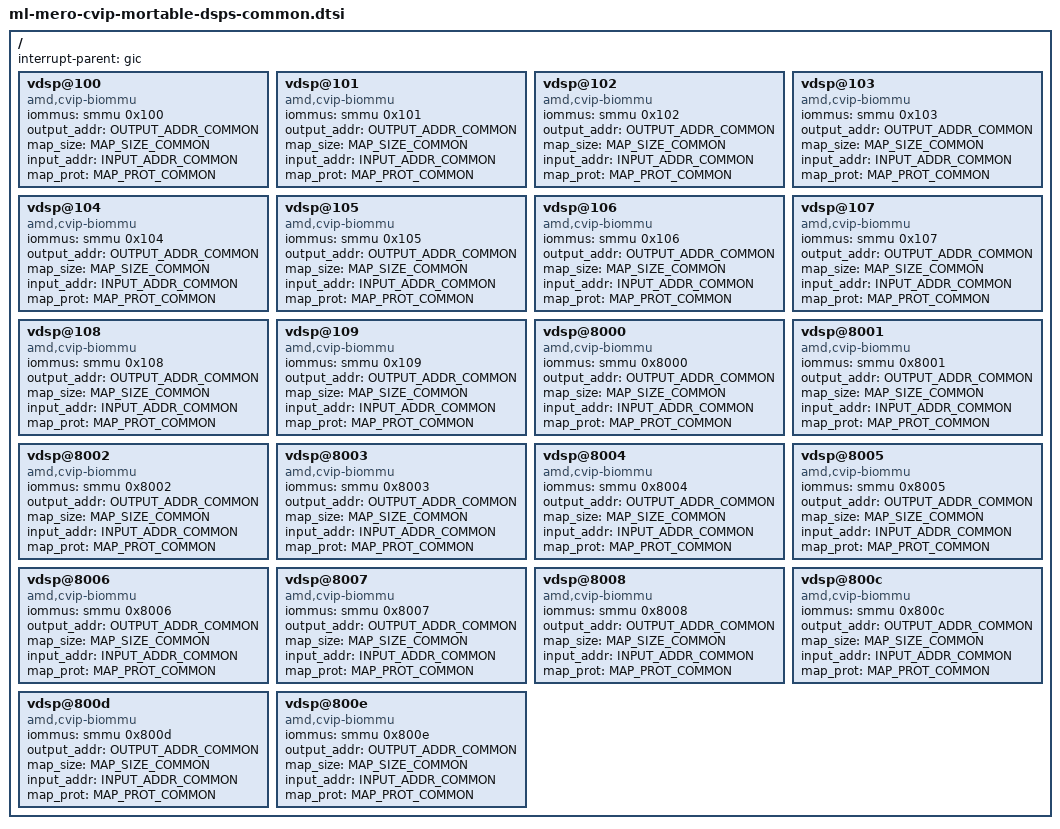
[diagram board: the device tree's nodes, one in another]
/*
 * DTS file for DSP Stream IDs
 *
 * Copyright (C) 2018-2020 Advanced Micro Devices, Inc. All rights reserved.
 */

#include <dt-bindings/interrupt-controller/irq.h>
#include <dt-bindings/interrupt-controller/arm-gic.h>
#include <dt-bindings/cvcore/cvcore_common.h>

/dts-v1/;

/ {
	interrupt-parent = <&gic>;
	#size-cells = <0x2>;
	#address-cells = <0x2>;

	vdsp@100 {
		status = "ok";
		compatible = "amd,cvip-biommu";
		iommus = <&smmu 0x100>;
		output_addr = OUTPUT_ADDR_COMMON;
		map_size = MAP_SIZE_COMMON;
		input_addr = INPUT_ADDR_COMMON;
		map_prot = MAP_PROT_COMMON;
	};

	vdsp@101 {
		status = "ok";
		compatible = "amd,cvip-biommu";
		iommus = <&smmu 0x101>;
		output_addr = OUTPUT_ADDR_COMMON;
		map_size = MAP_SIZE_COMMON;
		input_addr = INPUT_ADDR_COMMON;
		map_prot = MAP_PROT_COMMON;
	};

    // Stream ID for cvcore_component validation
	vdsp@102 {
		status = "ok";
		compatible = "amd,cvip-biommu";
		iommus = <&smmu 0x102>;
		output_addr = OUTPUT_ADDR_COMMON;
		map_size = MAP_SIZE_COMMON;
		input_addr = INPUT_ADDR_COMMON;
		map_prot = MAP_PROT_COMMON;
	};

	vdsp@103 {
		status = "ok";
		compatible = "amd,cvip-biommu";
		iommus = <&smmu 0x103>;
		output_addr = OUTPUT_ADDR_COMMON;
		map_size = MAP_SIZE_COMMON;
		input_addr = INPUT_ADDR_COMMON;
		map_prot = MAP_PROT_COMMON;
	};

	vdsp@104 {
		status = "ok";
		compatible = "amd,cvip-biommu";
		iommus = <&smmu 0x104>;
		output_addr = OUTPUT_ADDR_COMMON;
		map_size = MAP_SIZE_COMMON;
		input_addr = INPUT_ADDR_COMMON;
		map_prot = MAP_PROT_COMMON;
	};

	vdsp@105 {
		status = "ok";
		compatible = "amd,cvip-biommu";
		iommus = <&smmu 0x105>;
		output_addr = OUTPUT_ADDR_COMMON;
		map_size = MAP_SIZE_COMMON;
		input_addr = INPUT_ADDR_COMMON;
		map_prot = MAP_PROT_COMMON;
	};

	vdsp@106 {
		status = "ok";
		compatible = "amd,cvip-biommu";
		iommus = <&smmu 0x106>;
		output_addr = OUTPUT_ADDR_COMMON;
		map_size = MAP_SIZE_COMMON;
		input_addr = INPUT_ADDR_COMMON;
		map_prot = MAP_PROT_COMMON;
	};

	vdsp@107 {
		status = "ok";
		compatible = "amd,cvip-biommu";
		iommus = <&smmu 0x107>;
		output_addr = OUTPUT_ADDR_COMMON;
		map_size = MAP_SIZE_COMMON;
		input_addr = INPUT_ADDR_COMMON;
		map_prot = MAP_PROT_COMMON;
	};

	vdsp@108 {
		status = "ok";
		compatible = "amd,cvip-biommu";
		iommus = <&smmu 0x108>;
		output_addr = OUTPUT_ADDR_COMMON;
		map_size = MAP_SIZE_COMMON;
		input_addr = INPUT_ADDR_COMMON;
		map_prot = MAP_PROT_COMMON;
	};

	vdsp@109 {
		status = "ok";
		compatible = "amd,cvip-biommu";
		iommus = <&smmu 0x109>;
		output_addr = OUTPUT_ADDR_COMMON;
		map_size = MAP_SIZE_COMMON;
		input_addr = INPUT_ADDR_COMMON;
		map_prot = MAP_PROT_COMMON;
	};

    // Stream IDs for Algo packages
	vdsp@8000 {
		status = "ok";
		compatible = "amd,cvip-biommu";
		iommus = <&smmu 0x8000>;
		output_addr = OUTPUT_ADDR_COMMON;
		map_size = MAP_SIZE_COMMON;
		input_addr = INPUT_ADDR_COMMON;
		map_prot = MAP_PROT_COMMON;
	};

	vdsp@8001 {
		status = "ok";
		compatible = "amd,cvip-biommu";
		iommus = <&smmu 0x8001>;
		output_addr = OUTPUT_ADDR_COMMON;
		map_size = MAP_SIZE_COMMON;
		input_addr = INPUT_ADDR_COMMON;
		map_prot = MAP_PROT_COMMON;
	};

	vdsp@8002 {
		status = "ok";
		compatible = "amd,cvip-biommu";
		iommus = <&smmu 0x8002>;
		output_addr = OUTPUT_ADDR_COMMON;
		map_size = MAP_SIZE_COMMON;
		input_addr = INPUT_ADDR_COMMON;
		map_prot = MAP_PROT_COMMON;
	};

	vdsp@8003 {
		status = "ok";
		compatible = "amd,cvip-biommu";
		iommus = <&smmu 0x8003>;
		output_addr = OUTPUT_ADDR_COMMON;
		map_size = MAP_SIZE_COMMON;
		input_addr = INPUT_ADDR_COMMON;
		map_prot = MAP_PROT_COMMON;
	};

	vdsp@8004 {
		status = "ok";
		compatible = "amd,cvip-biommu";
		iommus = <&smmu 0x8004>;
		output_addr = OUTPUT_ADDR_COMMON;
		map_size = MAP_SIZE_COMMON;
		input_addr = INPUT_ADDR_COMMON;
		map_prot = MAP_PROT_COMMON;
	};

	vdsp@8005 {
		status = "ok";
		compatible = "amd,cvip-biommu";
		iommus = <&smmu 0x8005>;
		output_addr = OUTPUT_ADDR_COMMON;
		map_size = MAP_SIZE_COMMON;
		input_addr = INPUT_ADDR_COMMON;
		map_prot = MAP_PROT_COMMON;
	};

	vdsp@8006 {
		status = "ok";
		compatible = "amd,cvip-biommu";
		iommus = <&smmu 0x8006>;
		output_addr = OUTPUT_ADDR_COMMON;
		map_size = MAP_SIZE_COMMON;
		input_addr = INPUT_ADDR_COMMON;
		map_prot = MAP_PROT_COMMON;
	};

	vdsp@8007 {
		status = "ok";
		compatible = "amd,cvip-biommu";
		iommus = <&smmu 0x8007>;
		output_addr = OUTPUT_ADDR_COMMON;
		map_size = MAP_SIZE_COMMON;
		input_addr = INPUT_ADDR_COMMON;
		map_prot = MAP_PROT_COMMON;
	};

	vdsp@8008 {
		status = "ok";
		compatible = "amd,cvip-biommu";
		iommus = <&smmu 0x8008>;
		output_addr = OUTPUT_ADDR_COMMON;
		map_size = MAP_SIZE_COMMON;
		input_addr = INPUT_ADDR_COMMON;
		map_prot = MAP_PROT_COMMON;
	};

	vdsp@800c {
		status = "ok";
		compatible = "amd,cvip-biommu";
		iommus = <&smmu 0x800c>;
		output_addr = OUTPUT_ADDR_COMMON;
		map_size = MAP_SIZE_COMMON;
		input_addr = INPUT_ADDR_COMMON;
		map_prot = MAP_PROT_COMMON;
	};

	vdsp@800d {
		status = "ok";
		compatible = "amd,cvip-biommu";
		iommus = <&smmu 0x800d>;
		output_addr = OUTPUT_ADDR_COMMON;
		map_size = MAP_SIZE_COMMON;
		input_addr = INPUT_ADDR_COMMON;
		map_prot = MAP_PROT_COMMON;
	};

	vdsp@800e {
		status = "ok";
		compatible = "amd,cvip-biommu";
		iommus = <&smmu 0x800e>;
		output_addr = OUTPUT_ADDR_COMMON;
		map_size = MAP_SIZE_COMMON;
		input_addr = INPUT_ADDR_COMMON;
		map_prot = MAP_PROT_COMMON;
	};
};

